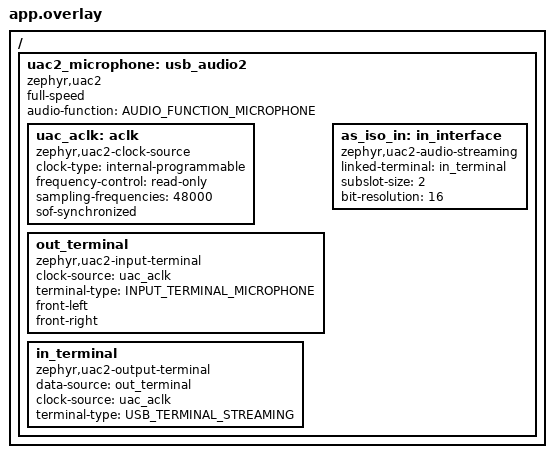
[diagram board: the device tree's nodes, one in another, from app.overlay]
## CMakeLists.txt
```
# SPDX-License-Identifier: Apache-2.0

cmake_minimum_required(VERSION 3.28.0)
find_package(Zephyr REQUIRED HINTS $ENV{ZEPHYR_BASE})
project(bap_broadcast_sink)

target_sources(app PRIVATE
  src/main.c
  src/stream_rx.c
)

target_sources_ifdef(CONFIG_ENABLE_LC3 app PRIVATE src/lc3.c)
target_sources_ifdef(CONFIG_STEREO_AUDIO_OUTPUT app PRIVATE src/stereo_out.c)

if(CONFIG_USE_CODEC_AUDIO_OUTPUT)
  target_sources(app PRIVATE src/hw_codec.c)
endif()

target_sources_ifdef(CONFIG_USE_I2S_CODEC_AUDIO_OUTPUT app PRIVATE src/i2s_codec.c)

if(CONFIG_USE_USB_AUDIO_OUTPUT)
  include(${ZEPHYR_BASE}/samples/subsys/usb/common/common.cmake)
  target_sources(app PRIVATE src/usb.c)
endif()
```

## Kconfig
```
# Copyright (c) 2022 Nordic Semiconductor ASA
# SPDX-License-Identifier: Apache-2.0

mainmenu "Bluetooth: Broadcast Audio Sink"

config SCAN_OFFLOAD
	bool "Whether to wait for a Broadcast Assistant"
	default y
	# enable PAST support if we can
	select BT_PER_ADV_SYNC_TRANSFER_RECEIVER if (!HAS_BT_CTLR || \
							BT_CTLR_SYNC_TRANSFER_RECEIVER_SUPPORT)
	help
	  If set to true, the sample will start advertising connectable for
	  Broadcast Assistants.

config SCAN_SELF
	bool "Whether to scan for Broadcast Sources without Broadcast Assistant"
	default y
	help
	  If set to true, the sample will start scanning for Broadcast Sources
	  without waiting for a Broadcast Assistant to connect.

config SCAN_DELAY
	int "Delay before starting scan (in seconds)"
	range 0 255
	default 10
	depends on SCAN_SELF
	help
	  Time to advertise connectable for a Broadcast Assistant to connect
	  before starting scanning for Broadcast Sources.

config SCAN_BACKGROUND
	bool "Keep background scanning"
	depends on SCAN_SELF
	help
	  Keep scanning in the background.

config TARGET_BROADCAST_NAME
	string "Target Broadcast Device Name"
	default ""
	help
	  Name of target broadcast device. If not empty string, sink device
	  will only listen to the specified broadcast source. Not case sensitive.

config MAX_CODEC_FRAMES_PER_SDU
	int "The maximum number of codec frame per SDU supported"
	default 1
	range 1 255
	help
	  Maximum number of codec frames per SDU supported by this device. Increasing this value
	  allows support for a greater variety of broadcasts, but also increases memory usage.

config ENABLE_LC3
	bool "Enable the LC3 codec"
	# By default let's enable it in the platforms we know are capable of supporting it
	default y
	depends on CPU_HAS_FPU && \
		(ARCH_POSIX || SOC_COMPATIBLE_NRF52X || SOC_COMPATIBLE_NRF5340_CPUAPP || \
			SOC_MIMXRT1062 || SOC_SF32LB525UC6)
	select LIBLC3
	select FPU

config USE_USB_AUDIO_OUTPUT
	bool "Use USB Audio as output"
	depends on ENABLE_LC3
	select USB_DEVICE_STACK_NEXT
	select USBD_AUDIO2_CLASS
	help
	  Enables USB audio as output as a USB peripheral. This does not support providing USB
	  audio to e.g. speakers that are also USB peripherals, but can be connected to e.g. a
	  phone or PC as a USB-in device (such as a USB microphone).
	  USB audio only supports a single audio channel.

config USE_CODEC_AUDIO_OUTPUT
	bool "Use Codec Audio as output"
	depends on ENABLE_LC3
	help
	  Enables codec audio as output. This uses the hardware audio codec for audio playback.
	  Supports audio output through the codec driver.

config USE_SPECIFIC_BROADCAST_CHANNEL
	bool "Use specific Broadcast Channel Audio Location"
	default y
	depends on USE_USB_AUDIO_OUTPUT
	help
	  Enables the use of a specific Channel Audio Location
	  (see config TARGET_BROADCAST_CHANNEL).

config TARGET_BROADCAST_CHANNEL
	int "Broadcast Channel Audio Location to sync to"
	range 0 3
	default 1
	depends on USE_SPECIFIC_BROADCAST_CHANNEL
	help
	  Channel Audio Location to sync to. These corresponds to the bt_audio_location,
	  supporting mono, left and right channels

config INFO_REPORTING_INTERVAL
	int "Number of SDUs received between each information report"
	default 1000
	help
	  Determines how often information about received data is logged.
	  Set to 0 to disable reporting.

# Source common USB sample options used to initialize new experimental USB device stack.
# The scope of these options is limited to USB samples in project tree,
# you cannot use them in your own application.
source "samples/subsys/usb/common/Kconfig.sample_usbd"

source "Kconfig.zephyr"
```

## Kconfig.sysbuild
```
# Copyright 2023 Nordic Semiconductor ASA
# SPDX-License-Identifier: Apache-2.0

source "share/sysbuild/Kconfig"

config NET_CORE_BOARD
	string
	default "nrf5340dk/nrf5340/cpunet" if "$(BOARD)" = "nrf5340dk"
	default "nrf5340_audio_dk/nrf5340/cpunet" if "$(BOARD)" = "nrf5340_audio_dk"
	default "nrf5340bsim/nrf5340/cpunet" if $(BOARD_TARGET_STRING) = "NRF5340BSIM_NRF5340_CPUAPP"
	default "nrf54h20dk/nrf54h20/cpunet" if "$(BOARD)" = "nrf54h20dk"

config NET_CORE_IMAGE_HCI_IPC
	bool "HCI IPC image on network core"
	default y
	depends on NET_CORE_BOARD != ""
```

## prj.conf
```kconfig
CONFIG_BT=y
CONFIG_UTF8=y
CONFIG_BT_AUDIO=y
CONFIG_BT_SMP=y
CONFIG_BT_PAC_SNK=y
CONFIG_BT_PERIPHERAL=y
CONFIG_BT_GAP_AUTO_UPDATE_CONN_PARAMS=n
# Set preferred values based on BT_BAP_CONN_PARAM_RELAXED
CONFIG_BT_PERIPHERAL_PREF_MIN_INT=50
CONFIG_BT_PERIPHERAL_PREF_MAX_INT=70
CONFIG_BT_PERIPHERAL_PREF_LATENCY=0
CONFIG_BT_PERIPHERAL_PREF_TIMEOUT=400
CONFIG_BT_OBSERVER=y
CONFIG_BT_GATT_DYNAMIC_DB=y
CONFIG_BT_EXT_ADV=y
CONFIG_BT_PER_ADV_SYNC=y
CONFIG_BT_ISO_SYNC_RECEIVER=y
CONFIG_BT_BAP_BROADCAST_SINK=y
CONFIG_BT_BAP_SCAN_DELEGATOR=y
CONFIG_BT_ISO_MAX_CHAN=2
# Allocate 4 RX buffers per channel
CONFIG_BT_ISO_RX_BUF_COUNT=8
CONFIG_BT_BAP_BROADCAST_SNK_SUBGROUP_COUNT=2
CONFIG_BT_BAP_BROADCAST_SNK_STREAM_COUNT=2
CONFIG_BT_BAP_BASS_MAX_SUBGROUPS=2
CONFIG_BT_BUF_ACL_RX_SIZE=255
CONFIG_BT_BUF_ACL_TX_SIZE=251
CONFIG_BT_AUDIO_CODEC_CFG_MAX_METADATA_SIZE=64
CONFIG_BT_AUDIO_CODEC_CFG_MAX_DATA_SIZE=64
CONFIG_BT_AUDIO_CODEC_CAP_MAX_METADATA_SIZE=64
CONFIG_BT_AUDIO_CODEC_CAP_MAX_DATA_SIZE=64

CONFIG_BT_DEVICE_NAME="Broadcast Audio Sink"

CONFIG_LOG=y
CONFIG_LOG_BUFFER_SIZE=4096

CONFIG_ASSERT=y
```

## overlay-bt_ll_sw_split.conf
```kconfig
# Zephyr Bluetooth Controller
CONFIG_BT_LL_SW_SPLIT=y

# Enable Extended Advertising, Scanning and Periodic Sync
CONFIG_BT_EXT_ADV=y
CONFIG_BT_PER_ADV_SYNC=y

# Enable Coded PHY support
CONFIG_BT_CTLR_PHY_CODED=y

# Advertising Data Length
CONFIG_BT_CTLR_ADV_DATA_LEN_MAX=50

# Increase Zephyr Bluetooth LE Controller Rx buffer to receive complete chain
# of PDUs
CONFIG_BT_CTLR_RX_BUFFERS=9

# Set maximum scan data length for Extended Scanning in Bluetooth LE Controller
CONFIG_BT_CTLR_SCAN_DATA_LEN_MAX=1650

# Enable support for Broadcast ISO Sync
CONFIG_BT_CTLR_SYNC_ISO=y
CONFIG_BT_CTLR_SCAN_SYNC_ISO_SET=1
CONFIG_BT_CTLR_SYNC_ISO_STREAM_COUNT=2
CONFIG_BT_CTLR_SYNC_ISO_STREAM_MAX=2
CONFIG_BT_CTLR_SYNC_ISO_PDU_LEN_MAX=251

# Supports the highest SDU size required by any BAP LC3 presets (155)
CONFIG_BT_CTLR_SYNC_ISO_PDU_LEN_MAX=251

# Number of supported streams
CONFIG_BT_CTLR_SYNC_ISO_STREAM_MAX=2
CONFIG_BT_CTLR_ISOAL_SINKS=2

# Use link time optimization for code size reduction
CONFIG_ISR_TABLES_LOCAL_DECLARATION=y
CONFIG_LTO=y

# Generate .lst file, to find HCI h/w error event given PC
CONFIG_OUTPUT_DISASSEMBLY=y
CONFIG_OUTPUT_DISASSEMBLY_WITH_SOURCE=y

# Use unreserved scanning and ticker slot window yield
CONFIG_BT_CTLR_ADVANCED_FEATURES=y
CONFIG_BT_CTLR_ADV_RESERVE_MAX=n
CONFIG_BT_CTLR_PERIPHERAL_RESERVE_MAX=n

CONFIG_BT_CTLR_LOW_LAT_ULL=y
CONFIG_BT_CTLR_SCAN_AUX_SET=3
# CONFIG_BT_CTLR_SCAN_AUX_USE_CHAINS=y
# CONFIG_BT_CTLR_SCAN_AUX_CHAIN_COUNT=1
CONFIG_BT_CTLR_SCAN_AUX_SYNC_RESERVE_MIN=y
CONFIG_BT_CTLR_SCAN_UNRESERVED=y
CONFIG_BT_CTLR_SCAN_SLOT_WINDOW=y

CONFIG_BT_CTLR_SYNC_ISO_RESERVE_MAX=n
CONFIG_BT_CTLR_SYNC_ISO_SLOT_WINDOW_JITTER=y

CONFIG_BT_CTLR_ADV_SLOT_WINDOW=y
CONFIG_BT_CTLR_ADV_AUX_SLOT_WINDOW_DRIFT=y

CONFIG_BT_CTLR_LLL_PRIO=0
CONFIG_BT_CTLR_ULL_HIGH_PRIO=1
CONFIG_BT_CTLR_ULL_LOW_PRIO=2

CONFIG_BT_CTLR_LLL_PREPARE_AT_MARGIN=y
CONFIG_BT_CTLR_RADIO_TIMER_ISR=y
CONFIG_BT_CTLR_SW_SWITCH_SINGLE_TIMER=n

CONFIG_BT_TICKER_NEXT_SLOT_GET_MATCH=y
CONFIG_BT_TICKER_EXT=y
CONFIG_BT_TICKER_EXT_EXPIRE_INFO=n
CONFIG_BT_TICKER_EXT_SLOT_WINDOW_YIELD=y

# Enable in-system tests and profiling
CONFIG_BT_CTLR_TEST=y
CONFIG_BT_CTLR_PROFILE_ISR=y

CONFIG_BT_CTLR_ASSERT_OPTIMIZE_FOR_SIZE=n

# CONFIG_ZERO_LATENCY_IRQS=y
# CONFIG_BT_CTLR_ZLI=y
```

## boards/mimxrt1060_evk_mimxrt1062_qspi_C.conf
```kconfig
# Enable Multimedia Pipeline (mpipe) framework on RT1060 EVKC only
CONFIG_MPIPE=y

# liblc3 provides the LC3 decoder and its headers (LC3_MAX_NUM_SAMPLES_MONO,
# LC3_DECODER_MEM_SIZE, etc.) used by the mpipe audio transform.
CONFIG_LIBLC3=y


# mpipe uses zbus message subscribers for the pipeline bus/observer
CONFIG_ZBUS_MSG_SUBSCRIBER=y

# Number of net_buf pools mpipe may register for negotiated buffer pools
CONFIG_MPIPE_NET_BUF_POOL_COUNT=3

# The mpipe streaming thread runs the LC3 decode (lc3_decode) in the transform
# chain function. LC3 decoding needs far more stack than the 1024-byte default,
# so raise the streaming thread stack to avoid a pipeline-thread stack overflow.
CONFIG_MPIPE_THREAD_STACK_SIZE=8192


# Audio output path: I2S/SAI -> hardware codec (WM8962)
CONFIG_I2S=y
# The MCUX SAI driver's TX in_queue/out_queue depth is sized by
# CONFIG_I2S_TX_BLOCK_COUNT: the number of blocks that can be in flight inside
# the SAI DMA queue. With the free-running playback thread the SAI is always
# fed (real PCM or silence), so a small in-flight depth is sufficient.
CONFIG_I2S_TX_BLOCK_COUNT=6

# Output latency budget for the PCM playback path, in LC3 frame blocks
# (10 ms each for this configuration):
#  - prebuffer 4 blocks (~40 ms) is the cushion that absorbs arrival jitter and
#    the drift between the broadcaster clock and the SAI sample clock; it sets
#    the nominal latency.
#  - the ring caps the worst case at 12 blocks (~120 ms) before the oldest
#    block is dropped.
CONFIG_BAP_BROADCAST_SINK_PCM_PREBUFFER_COUNT=4
CONFIG_BAP_BROADCAST_SINK_PCM_BUFFER_PLAY_COUNT=12

# Prime 2 silence blocks into the SAI DMA before starting it, so the frame clock
# is running before the first decoded PCM arrives.
CONFIG_BAP_BROADCAST_SINK_PCM_BUFFER_PRELOAD_COUNT=2

CONFIG_AUDIO=y
CONFIG_AUDIO_CODEC=y
CONFIG_USE_CODEC_AUDIO_OUTPUT=y
CONFIG_USE_I2S_CODEC_TRANSPORT=y
CONFIG_BT_ISO_RX_BUF_COUNT=20
```

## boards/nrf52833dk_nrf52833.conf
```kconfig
# Have Extended Advertising in the background
CONFIG_SCAN_OFFLOAD=n
CONFIG_SCAN_SELF=y
CONFIG_SCAN_BACKGROUND=y

# Enable Full Extended Scanning
CONFIG_BT_EXT_SCAN_BUF_SIZE=1650

# Zephyr Bluetooth LE Controller needs 16 event buffers to generate Extended
# Advertising Report for receiving the complete 1650 bytes of data
CONFIG_BT_BUF_EVT_RX_COUNT=16

CONFIG_BT_LOG_SNIFFER_INFO=y

CONFIG_THREAD_ANALYZER=y
CONFIG_THREAD_ANALYZER_AUTO=y
CONFIG_THREAD_ANALYZER_AUTO_INTERVAL=5
CONFIG_THREAD_NAME=y

CONFIG_LOG=y
CONFIG_LOG_BUFFER_SIZE=4096
```

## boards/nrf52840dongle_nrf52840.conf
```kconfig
# Use USB Audio as audio sink
CONFIG_USE_USB_AUDIO_OUTPUT=y
CONFIG_SAMPLE_USBD_PRODUCT="USB Broadcast Sink sample"

CONFIG_BOARD_SERIAL_BACKEND_CDC_ACM=n
```

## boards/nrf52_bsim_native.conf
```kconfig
# Have Extended Advertising in the background
CONFIG_SCAN_OFFLOAD=y
CONFIG_SCAN_SELF=y
CONFIG_SCAN_BACKGROUND=y

# Enable Full Extended Scanning
CONFIG_BT_EXT_SCAN_BUF_SIZE=1650

# Zephyr Bluetooth LE Controller needs 16 event buffers to generate Extended
# Advertising Report for receiving the complete 1650 bytes of data
CONFIG_BT_BUF_EVT_RX_COUNT=16

CONFIG_CLOCK_CONTROL_NRF_K32SRC_100PPM=y

CONFIG_BT_LOG_SNIFFER_INFO=y
```

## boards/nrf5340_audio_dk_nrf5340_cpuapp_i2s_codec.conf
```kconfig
# Copyright The Zephyr Project Contributors
#
# SPDX-License-Identifier: Apache-2.0

# Use the CS47L63 headphone output instead of USB Audio
CONFIG_USE_I2S_CODEC_AUDIO_OUTPUT=y
```

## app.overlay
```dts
/*
 * Copyright (c) 2025 Nordic Semiconductor ASA
 *
 * SPDX-License-Identifier: Apache-2.0
 */

#include <zephyr/dt-bindings/usb/audio.h>

/ {
	uac2_microphone: usb_audio2 {
		compatible = "zephyr,uac2";
		full-speed;
		audio-function = <AUDIO_FUNCTION_MICROPHONE>;
		status = "okay";

		/* Clock supporting 48KHz
		 *
		 * Since the incoming audio may be between 8 and 48 KHz, we always upsample to 48KHz
		 */
		uac_aclk: aclk {
			compatible = "zephyr,uac2-clock-source";
			clock-type = "internal-programmable";
			frequency-control = "read-only";
			sampling-frequencies = <48000>;
			/* Falsely claim synchronous audio because we
			 * currently don't calculate feedback value
			 */
			sof-synchronized;
		};

		/* The out_terminal supports the incoming Bluetooth LE Audio over ISO
		 * and treats it as a microphone towards the USB host
		 */
		out_terminal: out_terminal {
			compatible = "zephyr,uac2-input-terminal";
			clock-source = <&uac_aclk>;
			terminal-type = <INPUT_TERMINAL_MICROPHONE>;
			front-left;
			front-right;
		};

		/* USB Audio terminal from USB device to USB host */
		in_terminal: in_terminal {
			compatible = "zephyr,uac2-output-terminal";
			data-source = <&out_terminal>;
			clock-source = <&uac_aclk>;
			terminal-type = <USB_TERMINAL_STREAMING>;
		};

		as_iso_in: in_interface {
			compatible = "zephyr,uac2-audio-streaming";
			linked-terminal = <&in_terminal>;
			subslot-size = <2>;
			bit-resolution = <16>;
		};
	};
};
```

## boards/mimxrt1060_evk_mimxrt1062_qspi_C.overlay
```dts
/*
 * Copyright (c) 2026 NXP
 *
 * SPDX-License-Identifier: Apache-2.0
 */

/ {
	aliases {
		/* hw_codec.c resolves the codec through DT_ALIAS(codec0).
		 * audio_codec is the WM8962 node defined in the board DTS.
		 */
		codec0 = &audio_codec;
	};
};

&sai1 {
	mclk-output;
	podf = <15>;
	pll-clocks = <&anatop 0 0 0>,
		     <&anatop 0 0 32>,
		     <&anatop 0 0 1>,
		     <&anatop 0 0 768>,
		     <&anatop 0 0 1000>;
};
```

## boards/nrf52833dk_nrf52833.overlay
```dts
/*
 * Copyright (c) 2025 Nordic Semiconductor ASA
 *
 * SPDX-License-Identifier: Apache-2.0
 */

/* #include "../app.overlay" */
```

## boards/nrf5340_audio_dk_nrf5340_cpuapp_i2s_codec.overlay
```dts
/*
 * Copyright The Zephyr Project Contributors
 *
 * SPDX-License-Identifier: Apache-2.0
 */

#include <zephyr/dt-bindings/input/input-event-codes.h>

/ {
	aliases {
		codec0 = &cs47l63;
		i2s-codec-tx = &i2s0;
	};
};

&clock {
	hfclkaudio-frequency = <12288000>;
};

&hfclkaudio {
	hfclkaudio-frequency = <12288000>;
};

&i2s0 {
	clock-source = "ACLK";
};

&button3 {
	zephyr,code = <INPUT_KEY_MUTE>;
};
```

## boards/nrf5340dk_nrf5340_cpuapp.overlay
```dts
/*
 * Copyright (c) 2025 Nordic Semiconductor ASA
 *
 * SPDX-License-Identifier: Apache-2.0
 */

/*
 * #include "../app.overlay"
 */
```

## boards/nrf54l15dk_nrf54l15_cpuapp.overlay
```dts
/*
 * Copyright (c) 2025 Nordic Semiconductor ASA
 *
 * SPDX-License-Identifier: Apache-2.0
 */

/ {
	chosen {
		zephyr,console = &uart30;
	};
};

&uart30 {
	current-speed = <1000000>;
	status = "okay";
};

&uart20 {
	status = "disabled";
};
```

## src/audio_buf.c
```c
/*
 * SPDX-FileCopyrightText: Copyright The Zephyr Project Contributors
 * SPDX-License-Identifier: Apache-2.0
 */

#include <errno.h>
#include <stddef.h>
#include <stdint.h>
#include <string.h>

#include <zephyr/autoconf.h>
#include <zephyr/kernel.h>
#include <zephyr/sys/printk.h>
#include <zephyr/sys/util.h>

#include "audio_buf.h"

#if DT_HAS_ALIAS(i2s_codec_tx) && IS_ENABLED(CONFIG_I2S) && IS_ENABLED(CONFIG_AUDIO_CODEC)

/* Whole PCM ring buffer size (holds N maximum play blocks). */
#define BAP_PCM_DECODER_BUFFER_SIZE                                                                \
	(BAP_PCM_DATA_PLAY_SIZE_48K * CONFIG_BAP_BROADCAST_SINK_PCM_BUFFER_PLAY_COUNT)

/* Actual usable ring buffer size for the current sample rate. */
static uint32_t pcm_buffer_size;

/* Ring buffer producer/consumer state. */
static volatile uint32_t pcm_r;
static volatile uint32_t pcm_w;
static volatile uint32_t pcm_rm;
static volatile uint32_t pcm_w_count;
static volatile uint32_t pcm_r_count;
static volatile uint32_t pcm_rm_count;

static bool reach_threshold;

static __aligned(4) uint8_t decoded_pcm_buf[BAP_PCM_DECODER_BUFFER_SIZE];

static uint32_t audio_pcm_buffer_free_size(void)
{
	return pcm_buffer_size - (pcm_w_count - pcm_rm_count);
}

static uint32_t audio_add_pcm_data(const uint8_t *data, uint32_t length)
{
	uint32_t free_space;

	free_space = audio_pcm_buffer_free_size();

	if (free_space < length) {
		length = free_space;
	}

	if ((pcm_w + length) <= pcm_buffer_size) {
		if (data != NULL) {
			memcpy(&decoded_pcm_buf[pcm_w], data, length);
		} else {
			memset(&decoded_pcm_buf[pcm_w], 0, length);
		}

		pcm_w += length;
	} else {
		uint32_t first = pcm_buffer_size - pcm_w;

		if (data != NULL) {
			memcpy(&decoded_pcm_buf[pcm_w], data, first);
			memcpy(&decoded_pcm_buf[0], &data[first], length - first);
		} else {
			memset(&decoded_pcm_buf[pcm_w], 0, first);
			memset(&decoded_pcm_buf[0], 0, length - first);
		}

		pcm_w = length - first;
	}
	pcm_w_count += length;

	if (pcm_w == pcm_buffer_size) {
		pcm_w = 0;
	}

	return length;
}

int audio_media_sync(uint8_t *data, uint16_t datalen)
{
	if (data != NULL) {
		pcm_rm += datalen;
		pcm_rm_count += datalen;

		if (pcm_rm >= pcm_buffer_size) {
			pcm_rm -= pcm_buffer_size;
		}
	}

	return 0;
}

void audio_get_pcm_data(uint8_t **data, uint32_t length)
{
	uint32_t data_space;
	uint32_t w_count = pcm_w_count;
	uint32_t r_count = pcm_r_count;

	data_space = w_count - r_count;

	if (!reach_threshold) {
		if (data_space > CONFIG_BAP_BROADCAST_SINK_BOARD_CODEC_PLAY_THRESHOLD *
				 pcm_buffer_size / 100U) {
			reach_threshold = true;
		} else {
			*data = NULL;
			return;
		}
	}

	if (data_space < length) {
		*data = NULL;
		reach_threshold = false;
	} else {
		pcm_r_count += length;
		*data = &decoded_pcm_buf[pcm_r];
		pcm_r += length;

		if (pcm_r >= pcm_buffer_size) {
			pcm_r = 0;
		}
	}
}

void audio_feed_pcm_lc3(const uint8_t *data, size_t len, uint8_t channels)
{
	if ((data == NULL) || (len == 0U) || (channels == 0U)) {
		return;
	}

	/* The playback path always operates on stereo interleaved samples.
	 * If the decoded LC3 frame is mono, duplicate each sample to both
	 * channels; if it is already stereo (or more), pass through and let
	 * the sink truncate any additional channels.
	 */
	if (channels == 1U) {
		const int16_t *src = (const int16_t *)data;
		const size_t samples = len / sizeof(int16_t);
		int16_t frame[2];

		for (size_t i = 0U; i < samples; i++) {
			frame[0] = src[i];
			frame[1] = src[i];
			(void)audio_add_pcm_data((const uint8_t *)frame, sizeof(frame));
		}
	} else {
		(void)audio_add_pcm_data(data, len);
	}
}

void audio_buf_reset(uint32_t fs)
{
	uint32_t block;

	pcm_r = 0;
	pcm_w = 0;
	pcm_rm = 0;
	pcm_w_count = 0;
	pcm_r_count = 0;
	pcm_rm_count = 0;
	reach_threshold = false;

	switch (fs) {
	case 8000:
		block = BAP_PCM_DATA_PLAY_SIZE_8K;
		break;
	case 16000:
		block = BAP_PCM_DATA_PLAY_SIZE_16K;
		break;
	case 24000:
		block = BAP_PCM_DATA_PLAY_SIZE_24K;
		break;
	case 32000:
		block = BAP_PCM_DATA_PLAY_SIZE_32K;
		break;
	case 48000:
		block = BAP_PCM_DATA_PLAY_SIZE_48K;
		break;
	default:
		printk("wrong frequency\n");
		return;
	}

	pcm_buffer_size = BAP_PCM_DECODER_BUFFER_SIZE - (BAP_PCM_DECODER_BUFFER_SIZE % block);
}

#else

void audio_buf_reset(uint32_t fs)
{
	ARG_UNUSED(fs);
}

void audio_feed_pcm_lc3(const uint8_t *data, size_t len, uint8_t channels)
{
	ARG_UNUSED(data);
	ARG_UNUSED(len);
	ARG_UNUSED(channels);
}

#endif
```

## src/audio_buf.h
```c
/*
 * SPDX-FileCopyrightText: Copyright The Zephyr Project Contributors
 * SPDX-License-Identifier: Apache-2.0
 */

#ifndef ZEPHYR_INCLUDE_AUDIO_BUF_H_
#define ZEPHYR_INCLUDE_AUDIO_BUF_H_

#include <stddef.h>
#include <stdint.h>

/* Played PCM block is 10 ms of stereo 16-bit samples. */
#define BAP_PCM_DATA_PLAY_SIZE(_fs) (((_fs) / 100U) * 2U * 2U)

#define BAP_PCM_DATA_PLAY_SIZE_8K  BAP_PCM_DATA_PLAY_SIZE(8000)
#define BAP_PCM_DATA_PLAY_SIZE_16K BAP_PCM_DATA_PLAY_SIZE(16000)
#define BAP_PCM_DATA_PLAY_SIZE_24K BAP_PCM_DATA_PLAY_SIZE(24000)
#define BAP_PCM_DATA_PLAY_SIZE_32K BAP_PCM_DATA_PLAY_SIZE(32000)
#define BAP_PCM_DATA_PLAY_SIZE_48K BAP_PCM_DATA_PLAY_SIZE(48000)

void audio_buf_reset(uint32_t fs);

/* Feed decoded LC3 PCM into the playback ring buffer. */
void audio_feed_pcm_lc3(const uint8_t *data, size_t len, uint8_t channels);

int audio_media_sync(uint8_t *data, uint16_t datalen);

void audio_get_pcm_data(uint8_t **data, uint32_t length);

#endif /* ZEPHYR_INCLUDE_AUDIO_BUF_H_ */
```

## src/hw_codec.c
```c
/**
 * @file
 * @brief Bluetooth BAP Broadcast Sink audio codec integration
 *
 * This file handles all the audio codec hardware integration for the sample.
 *
 * Two codec integration models are supported and selected at compile time:
 *
 *  - Path A (control-only codec): the codec driver only implements the codec
 *    control API (for example the WM8962 on NXP i.MX RT boards). Such a codec
 *    cannot pull or write PCM samples itself, so the PCM data is transported to
 *    the codec over the SoC SAI/I2S peripheral by hw_codec_i2s.c. This module
 *    owns the codec control (audio_codec_configure / start_output / stop_output
 *    / volume) while hw_codec_i2s.c owns the SAI/I2S data path.
 *    This path is selected when the board provides an "i2s-codec-tx"
 *    devicetree alias and both CONFIG_I2S and CONFIG_AUDIO_CODEC are enabled.
 *
 *  - Path B (smart codec): the codec driver implements a done callback and an
 *    audio_codec_write() entry point, so PCM samples are pulled from an
 *    internal ring buffer whenever the codec requests a new block. This is the
 *    default path used when no I2S transport alias is present.
 *
 * Both models are hidden behind the same hw_codec_open / hw_codec_cfg /
 * hw_codec_write_data / hw_codec_close facade, so the mpipe and non-mpipe
 * callers do not need to know which model is in use.
 *
 * Copyright (c) 2025 SiFli Technologies(Nanjing) Co., Ltd
 * Copyright (c) 2026 NXP
 *
 * SPDX-License-Identifier: Apache-2.0
 */


#include <errno.h>
#include <stdbool.h>
#include <stddef.h>
#include <stdint.h>

#include <zephyr/autoconf.h>
#include <zephyr/device.h>
#include <zephyr/devicetree.h>
#include <zephyr/kernel.h>
#include <zephyr/logging/log.h>
#include <zephyr/audio/codec.h>
#include <zephyr/sys/ring_buffer.h>
#include <zephyr/toolchain.h>

LOG_MODULE_REGISTER(codec, CONFIG_LOG_DEFAULT_LEVEL);

/*
 * Select Path A (control-only codec + SAI/I2S PCM transport) when the user
 * enables CONFIG_USE_I2S_CODEC_TRANSPORT. Otherwise fall back to Path B
 * (smart codec with its own host interface).
 */

/*
 * Default speaker/output volume sent via AUDIO_PROPERTY_OUTPUT_VOLUME.
 *
 * The valid numeric range and exact mapping to dB are codec-dependent; refer
 * to the specific codec driver / datasheet for details. The value 15 was
 * selected as a conservative, comfortable default for this sample application
 * to avoid an excessively loud/noisy output during testing.
 * Adjust as needed to match the desired default output level.
 */
#define SPEAKER_VOL 15U



#if CONFIG_USE_I2S_CODEC_TRANSPORT
/* ---------------------------------------------------------------------------
 * Path A: control-only codec (for example WM8962) with SAI/I2S PCM transport.
 * -------------------------------------------------------------------------
 */


#include "hw_codec_i2s.h"

static const struct device *g_dev;
static bool codec_configured;

int hw_codec_open(void)
{
	int ret;

	/*
	 * Idempotent: the codec is opened from the stream "started" callback,
	 * and the audio data path may also open it while bringing itself up.
	 * Opening twice is harmless but re-initialising the transport under a
	 * running stream is not, so return early once the device is held.
	 */
	if (g_dev != NULL) {
		return 0;
	}

	g_dev = DEVICE_DT_GET(DT_ALIAS(codec0));
	if (!device_is_ready(g_dev)) {
		LOG_ERR("Could not open codec device");
		g_dev = NULL;
		return -EIO;
	}

	ret = hw_codec_i2s_init();
	if (ret != 0) {
		LOG_ERR("Failed to init I2S transport (err %d)", ret);
		g_dev = NULL;
		return ret;
	}

	return 0;
}

int hw_codec_cfg(uint32_t samplerate, uint32_t frame_dur_us, uint8_t channels)
{
	int ret;
	audio_property_value_t val = {.vol = SPEAKER_VOL};
	struct audio_codec_cfg cfg = {
		.dai_type = AUDIO_DAI_TYPE_I2S,
		.dai_route = AUDIO_ROUTE_PLAYBACK,
		.dai_cfg.i2s.word_size = CODEC_PCM_WIDTH_BITS,
		.dai_cfg.i2s.channels = channels,
		.dai_cfg.i2s.format = I2S_FMT_DATA_FORMAT_I2S,
#ifdef CONFIG_USE_CODEC_CLOCK
		.dai_cfg.i2s.options = I2S_OPT_BIT_CLK_CONTROLLER | I2S_OPT_FRAME_CLK_CONTROLLER,
#else
		.dai_cfg.i2s.options = I2S_OPT_BIT_CLK_TARGET | I2S_OPT_FRAME_CLK_TARGET,
#endif
		.dai_cfg.i2s.frame_clk_freq = samplerate,
		/*
		 * mem_slab and block_size are intentionally left unset here:
		 * they only matter to the SoC I2S peripheral, which is
		 * configured separately in hw_codec_i2s_cfg(). The codec control
		 * driver (for example WM8962) ignores these two fields. This is
		 * unlike a2dp_sink, which reuses a single struct for both the
		 * audio_codec_configure() and the i2s_configure() calls and thus
		 * has to populate them.
		 */
	};

	if (codec_configured) {
		LOG_WRN("Already configured");
		return -EALREADY;
	}

	LOG_INF("codec (I2S): samplerate=%u channels=%u frame_dur=%u us", samplerate,
		channels, frame_dur_us);

	ret = audio_codec_configure(g_dev, &cfg);
	if (ret != 0) {
		LOG_ERR("Failed to configure codec (err %d)", ret);
		return ret;
	}

	k_msleep(1000);

	ret = hw_codec_i2s_cfg(samplerate, channels, frame_dur_us);
	if (ret != 0) {
		LOG_ERR("Failed to configure I2S transport (err %d)", ret);
		return ret;
	}

	audio_codec_start_output(g_dev);

	ret = audio_codec_set_property(g_dev, AUDIO_PROPERTY_OUTPUT_VOLUME, 0, val);
	if (ret != 0) {
		LOG_ERR("Failed to set codec output volume (err %d)", ret);
		audio_codec_stop_output(g_dev);
		return ret;
	}

	codec_configured = true;

	return 0;
}

uint32_t hw_codec_write_data(const uint8_t *data, uint32_t len)
{
	return hw_codec_i2s_write(data, len);
}

int hw_codec_close(void)
{
	if (g_dev != NULL && codec_configured) {
		(void)hw_codec_i2s_close();
		audio_codec_stop_output(g_dev);
		codec_configured = false;
		return 0;
	} else {
		return -EIO;
	}
}

#else /* !CONFIG_USE_I2S_CODEC_TRANSPORT */
/* ---------------------------------------------------------------------------
 * Path B: smart codec (pull-driven via done callback + audio_codec_write).
 * -------------------------------------------------------------------------
 */


/*
 * Size of one audio block transferred to the codec, in bytes.
 *
 * For the configuration used here (16bit samples, mono channel),
 * 480 bytes correspond to 240 PCM samples per block. This value was
 * chosen as a compromise between:
 *  - keeping latency reasonably low (smaller blocks)
 *  - avoiding excessive interrupt / DMA overhead (larger blocks).
 * If the PCM format (sample width or number of channels) is changed,
 * this constant should be revisited so that the block size remains
 * appropriate for the target use case and hardware.
 */
#define CODEC_BLOCK_SIZE 480U

/*
 * Total size of the ring buffer used to queue audio data for the codec.
 *
 * The buffer is sized to hold 20 CODEC_BLOCK_SIZE blocks. Having multiple
 * blocks queued reduces the likelihood of underruns when the producer is
 * briefly delayed, while still keeping overall latency and RAM usage
 * bounded. Increasing the multiplier adds buffering (and latency / RAM
 * consumption); decreasing it reduces buffering but makes underruns more
 * likely on a busy system.
 */
#define RING_BUF_SIZE (CODEC_BLOCK_SIZE * 20U)

static uint8_t ring_buffer[RING_BUF_SIZE];
static struct ring_buf rb;
static bool codec_configured;
static uint8_t block_data[CODEC_BLOCK_SIZE];
static const struct device *g_dev;

static void tx_done(const struct device *dev, void *user_data)
{
	uint32_t avail;
	uint32_t read;
	int written;

	ARG_UNUSED(user_data);

	avail = ring_buf_size_get(&rb);
	if (avail < CODEC_BLOCK_SIZE) {
		LOG_WRN("Buffer does not have enough data for a full block");
		return;
	}

	read = ring_buf_get(&rb, block_data, CODEC_BLOCK_SIZE);
	if (read != CODEC_BLOCK_SIZE) {
		LOG_WRN("Failed to read full block from ring buffer: %u bytes", read);
		return;
	}

	written = audio_codec_write(dev, block_data, CODEC_BLOCK_SIZE);
	if (written != CODEC_BLOCK_SIZE) {
		LOG_WRN("Failed to write full block data to audio device: %u bytes", written);
		return;
	}
}

int hw_codec_open(void)
{
	/*
	 * Idempotent: the codec is opened from the stream "started" callback,
	 * and the audio data path may also open it while bringing itself up.
	 * Returning early keeps a second open from resetting the ring buffer
	 * under a codec that is already streaming.
	 */
	if (g_dev != NULL) {
		return 0;
	}

	g_dev = DEVICE_DT_GET(DT_ALIAS(codec0));
	if (!device_is_ready(g_dev)) {
		LOG_ERR("Could not open codec device");
		g_dev = NULL;
		return -EIO;
	}
	ring_buf_init(&rb, RING_BUF_SIZE, ring_buffer);
	return 0;
}

int hw_codec_cfg(uint32_t samplerate, uint32_t frame_dur_us, uint8_t channels)
{
	int ret;
	audio_property_value_t val = {.vol = SPEAKER_VOL};
	struct audio_codec_cfg cfg = {
		.dai_type = AUDIO_DAI_TYPE_PCM,
		.dai_cfg.pcm.dir = AUDIO_DAI_DIR_TX,
		.dai_cfg.pcm.pcm_width = AUDIO_PCM_WIDTH_16_BITS,
		.dai_cfg.pcm.channels = 1U,
		.dai_cfg.pcm.block_size = CODEC_BLOCK_SIZE,
		.dai_cfg.pcm.samplerate = samplerate,
	};

	/*
	 * The smart-codec path pulls fixed-size blocks (CODEC_BLOCK_SIZE) from
	 * its own ring buffer, so the codec frame duration does not affect its
	 * configuration.
	 */
	ARG_UNUSED(frame_dur_us);
	ARG_UNUSED(channels);

	if (codec_configured) {
		LOG_WRN("Already configured");
		return -EALREADY;
	}

	LOG_INF("codec: samplerate=%d block_size=%d", samplerate, CODEC_BLOCK_SIZE);
	audio_codec_register_done_callback(g_dev, tx_done, NULL, NULL, NULL);
	ret = audio_codec_configure(g_dev, &cfg);
	if (ret != 0) {
		LOG_ERR("Failed to configure codec (err %d)", ret);
		return ret;
	}

	ret = audio_codec_start(g_dev, AUDIO_DAI_DIR_TX);
	if (ret != 0) {
		LOG_ERR("Failed to start codec (err %d)", ret);
		return ret;
	}

	ret = audio_codec_set_property(g_dev, AUDIO_PROPERTY_OUTPUT_VOLUME, 0, val);
	if (ret != 0) {
		LOG_ERR("Failed to set codec output volume (err %d)", ret);
		if (audio_codec_stop(g_dev, AUDIO_DAI_DIR_TX) < 0) {
			LOG_ERR("Failed to stop codec");
		}
		return ret;
	}
	codec_configured = true;

	return 0;
}

uint32_t hw_codec_write_data(const uint8_t *data, uint32_t len)
{
	uint32_t bytes_put;

	bytes_put = ring_buf_put(&rb, data, len);
	if (bytes_put != len) {
		LOG_WRN("Buffer full, only added %u bytes", bytes_put);
	}
	return bytes_put;
}

int hw_codec_close(void)
{
	if (g_dev != NULL && codec_configured) {
		int ret = audio_codec_stop(g_dev, AUDIO_DAI_DIR_TX);

		if (ret < 0) {
			return ret;
		}
		ring_buf_reset(&rb);
		codec_configured = false;
		return 0;
	} else {
		return -EIO;
	}
}

#endif /* CONFIG_USE_I2S_CODEC_TRANSPORT */
```

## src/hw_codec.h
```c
/**
 * @file
 * @brief Bluetooth BAP Broadcast Sink sample audio codec header
 *
 * This file declares the audio codec related functionality for the sample
 *
 * Copyright (c) 2025 SiFli Technologies(Nanjing) Co., Ltd
 *
 * SPDX-License-Identifier: Apache-2.0
 */

#ifndef SAMPLE_BAP_BROADCAST_SINK_HW_CODEC_H
#define SAMPLE_BAP_BROADCAST_SINK_HW_CODEC_H
#include <stddef.h>
#include <stdint.h>

/**
 * @brief Open and initialize the audio codec.
 *
 * This function prepares the audio codec for use, allocating and
 * initializing any required resources.
 *
 * @retval 0        On success.
 * @return negative On failure, with a negative error code.
 */
int hw_codec_open(void);

/**
 * @brief Configure the audio codec sampling rate.
 *
 * This function applies the desired sampling rate to the audio codec.
 * It must be called after @ref hw_codec_open and before sending
 * audio data with @ref hw_codec_write_data.
 *
 * @param samplerate Sampling rate in Hz (for example, 48000 for 48 kHz).
 *
 * @retval 0        On success.
 * @retval -EALREADY If the codec is already configured.
 * @return negative  On other failures, with a negative error code.
 */
int hw_codec_cfg(uint32_t samplerate);

/**
 * @brief Write audio data to the codec for playback.
 *
 * This function sends raw audio samples to the codec. It should be
 * called after the codec has been opened and configured.
 *
 * @param data Pointer to the buffer containing audio data.
 * @param len  Number of bytes of audio data to write.
 *
 * @return The number of bytes successfully queued in the internal buffer.
 *         A value less than @p len indicates a partial enqueue. The actual
 *         transfer of the queued data to the codec hardware happens
 *         asynchronously.
 */
uint32_t hw_codec_write_data(const uint8_t *data, uint32_t len);

/**
 * @brief Close the audio codec and release resources.
 *
 * This function stops the codec if necessary and frees any resources
 * that were allocated by @ref hw_codec_open.
 *
 * @retval 0    On success.
 * @retval -EIO If the codec has not been opened or configured.
 */
int hw_codec_close(void);

#endif /* SAMPLE_BAP_BROADCAST_SINK_HW_CODEC_H */
```

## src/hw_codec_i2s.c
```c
/**
 * @file
 * @brief BAP Broadcast Sink I2S/SAI PCM transport (hardware layer).
 *
 * This module implements the hardware-specific SAI/I2S data path used by
 * hw_codec.c on boards whose codec is a control-only device (for example the
 * WM8962 on NXP i.MX RT boards). The codec driver on such boards only
 * implements the control API, so the PCM samples are transported to the codec
 * over the SoC SAI/I2S peripheral using the Zephyr I2S driver API
 * (i2s_configure / i2s_write / i2s_trigger).
 *
 * Responsibility split:
 *  - hw_codec.c owns the codec control (audio_codec_configure /
 *    start_output / stop_output / volume).
 *  - this module owns the SAI/I2S peripheral configuration and the DMA memory
 *    slab (a hardware/DMA resource).
 *  - i2s_play.c owns the software playback policy: the elastic PCM ring buffer
 *    and the playback thread that keeps the SAI DMA fed. This module hands the
 *    configured device, the DMA slab, the per-block size and the frame
 *    duration to i2s_play via i2s_play_setup().
 *
 * This file is only compiled when the board provides an i2s-codec-tx
 * devicetree alias (see CMakeLists.txt).
 *
 * Copyright (c) 2025 NXP
 *
 * SPDX-License-Identifier: Apache-2.0
 */

#include <errno.h>
#include <stdbool.h>
#include <stddef.h>
#include <stdint.h>

#include <zephyr/autoconf.h>
#include <zephyr/device.h>
#include <zephyr/devicetree.h>
#include <zephyr/kernel.h>
#include <zephyr/logging/log.h>
#include <zephyr/drivers/i2s.h>
#include <zephyr/toolchain.h>

#include "hw_codec_i2s.h"
#include "i2s_play.h"

LOG_MODULE_REGISTER(codec_i2s, CONFIG_LOG_DEFAULT_LEVEL);

#define I2S_TX_NODE DT_ALIAS(i2s_codec_tx)

#define I2S_TX_TIMEOUT_MS (2000U)

/* Fallback default in case the Kconfig option is not selected. */
#ifndef CONFIG_BAP_BROADCAST_SINK_PCM_BUFFER_PLAY_COUNT
#define CONFIG_BAP_BROADCAST_SINK_PCM_BUFFER_PLAY_COUNT 12
#endif

/* Depth of the elastic PCM ring between producer and playback thread. */
#define PCM_RING_DEPTH CONFIG_BAP_BROADCAST_SINK_PCM_BUFFER_PLAY_COUNT

/*
 * One I2S transfer block holds the interleaved PCM samples produced by the LC3
 * decoder for a single LC3 frame. The block size in bytes is computed at run
 * time from the actual stream parameters:
 *
 *   samples_per_frame = samplerate * frame_dur_us / 1000000
 *   block_size        = samples_per_frame * (word_size / 8) * channels
 *
 * The size is driven by the LC3 frame duration (per the BT LE Audio spec this
 * is either 7500 us or 10000 us), NOT by the ISO interval. ISO interval jitter
 * is absorbed by the PCM ring and the multi-block DMA slab.
 */
#define CODEC_PCM_MAX_CHANNELS 2U
#define CODEC_PCM_MAX_SAMPLERATE 48000U
#define CODEC_PCM_MAX_FRAME_DUR_US 10000U
#define CODEC_PCM_BYTES_PER_SAMPLE (CODEC_PCM_WIDTH_BITS / 8U)

/*
 * Worst-case bytes for a single block, used to statically size the DMA slab.
 * Worst case is 48 kHz, 10 ms, stereo:
 * 48000 * 10000 / 1000000 = 480 samples * 2 bytes * 2 channels = 1920 bytes.
 */
#define I2S_TX_MAX_BLOCK_SIZE\
	(((CODEC_PCM_MAX_SAMPLERATE * CODEC_PCM_MAX_FRAME_DUR_US) / 1000000U) *\
	 CODEC_PCM_BYTES_PER_SAMPLE * CODEC_PCM_MAX_CHANNELS)

/*
 * Total slab blocks: the ring can hold up to PCM_RING_DEPTH filled blocks that
 * have not yet been handed to the SAI, plus up to CONFIG_I2S_TX_BLOCK_COUNT
 * blocks in flight inside the SAI DMA queue, plus a couple of scratch/silence
 * blocks owned by the playback thread. Size the slab for the sum so the
 * producer and consumer never contend for the same pool.
 */
#define I2S_TX_SLAB_BLOCKS (PCM_RING_DEPTH + CONFIG_I2S_TX_BLOCK_COUNT + 2U)

#if defined(CONFIG_NOCACHE_MEMORY)
#define __NOCACHE __attribute__((__section__(".nocache")))
#elif defined(CONFIG_DT_DEFINED_NOCACHE)
#define __NOCACHE __attribute__((__section__(CONFIG_DT_DEFINED_NOCACHE_NAME)))
#else
#define __NOCACHE
#endif

/* DMA memory slab shared by the PCM and silence blocks (hardware resource). */
static __NOCACHE __aligned(4) uint8_t tx_slab_buffer[I2S_TX_SLAB_BLOCKS * I2S_TX_MAX_BLOCK_SIZE];
static struct k_mem_slab tx_mem_slab;

static const struct device *i2s_tx_dev;

/* Set once the DMA slab has been initialised, to detect a reconfiguration. */
static bool tx_slab_initialised;

int hw_codec_i2s_init(void)
{
	i2s_tx_dev = DEVICE_DT_GET(I2S_TX_NODE);
	if (!device_is_ready(i2s_tx_dev)) {
		LOG_ERR("I2S tx device not ready");
		return -EIO;
	}

	return 0;
}

int hw_codec_i2s_cfg(uint32_t samplerate, uint8_t channels, uint32_t frame_dur_us)
{
	int ret;
	uint32_t samples_per_frame;
	uint32_t block_size;

	if ((channels == 0U || channels > CODEC_PCM_MAX_CHANNELS) ||
	    (samplerate == 0U || samplerate > CODEC_PCM_MAX_SAMPLERATE) ||
	    (frame_dur_us == 0U)) {
		LOG_ERR("Unsupported Parameter");
		return -EINVAL;
	}

	/* Clamp to the worst case the DMA slab is sized for (10 ms). */
	if (frame_dur_us > CODEC_PCM_MAX_FRAME_DUR_US) {
		LOG_WRN("Frame duration %u us exceeds max, clamping to %u us", frame_dur_us,
			CODEC_PCM_MAX_FRAME_DUR_US);
		frame_dur_us = CODEC_PCM_MAX_FRAME_DUR_US;
	}

	/*
	 * Number of PCM samples per channel in one LC3 frame. Microsecond math
	 * keeps the 7.5 ms case exact (48 kHz * 7500 / 1000000 = 360 samples).
	 */
	samples_per_frame = (uint32_t)(((uint64_t)samplerate * frame_dur_us) / 1000000U);

	/* samples_per_frame * bytes_per_sample * channels */
	block_size = samples_per_frame * CODEC_PCM_BYTES_PER_SAMPLE * channels;

	if (block_size == 0U || block_size > I2S_TX_MAX_BLOCK_SIZE) {
		LOG_ERR("Computed block size %u out of range (max %u)", block_size,
			I2S_TX_MAX_BLOCK_SIZE);
		return -EINVAL;
	}

	/*
	 * Reconfiguring the slab would reset its free list while the SAI DMA
	 * and the playback thread may still hold blocks carved out of the old
	 * partition, leaking those blocks and letting two owners write the same
	 * memory. Require a close (which stops playback and drains the ring)
	 * before the stream can be configured again.
	 */
	if (tx_slab_initialised && k_mem_slab_num_used_get(&tx_mem_slab) != 0U) {
		LOG_ERR("I2S tx reconfigure with %u blocks still in use",
			k_mem_slab_num_used_get(&tx_mem_slab));
		return -EBUSY;
	}

	/*
	 * Initialise the DMA slab before i2s_configure(): the configuration
	 * stores the mem_slab pointer in the driver and the driver may allocate
	 * from it as soon as the stream is configured, so the slab must already
	 * describe a valid partition at that point.
	 */
	k_mem_slab_init(&tx_mem_slab, tx_slab_buffer, block_size, I2S_TX_SLAB_BLOCKS);
	tx_slab_initialised = true;

	struct i2s_config i2s_cfg = {
		.word_size = CODEC_PCM_WIDTH_BITS,
		.channels = channels,
		.format = I2S_FMT_DATA_FORMAT_I2S,
		/*
		 * Clock roles are deliberately the mirror image of the codec
		 * configuration in hw_codec.c: the SAI and the codec are peers
		 * on the same I2S bus, so exactly one of them must drive BCK
		 * and WS. CONFIG_USE_CODEC_CLOCK selects the codec as the clock
		 * source, which makes the SAI the target here.
		 */
#ifdef CONFIG_USE_CODEC_CLOCK
		.options = I2S_OPT_BIT_CLK_TARGET | I2S_OPT_FRAME_CLK_TARGET,
#else
		.options = I2S_OPT_BIT_CLK_CONTROLLER | I2S_OPT_FRAME_CLK_CONTROLLER,
#endif
		.frame_clk_freq = samplerate,
		.block_size = block_size,
		.mem_slab = &tx_mem_slab,
		.timeout = I2S_TX_TIMEOUT_MS,
	};

	ret = i2s_configure(i2s_tx_dev, I2S_DIR_TX, &i2s_cfg);
	if (ret != 0) {
		LOG_ERR("Failed to configure I2S tx (err %d)", ret);
		return ret;
	}

	/* Hand the hardware handles to the pure-software playback layer. */
	i2s_play_setup(i2s_tx_dev, &tx_mem_slab, block_size, frame_dur_us);

	LOG_INF("I2S tx: rate=%u channels=%u block_size=%u", samplerate, channels, block_size);

	return 0;
}

uint32_t hw_codec_i2s_write(const uint8_t *data, uint32_t len)
{
	return i2s_play_write(data, len);
}

int hw_codec_i2s_close(void)
{
	/*
	 * i2s_play_stop() joins the playback thread, which drops the transmit
	 * stream and returns every block it owned to the slab, so the stream is
	 * already stopped and the slab fully reclaimed when this returns.
	 */
	i2s_play_stop();

	return 0;
}
```

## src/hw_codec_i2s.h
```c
/**
 * @file
 * @brief BAP Broadcast Sink I2S/SAI PCM transport public interface.
 *
 * This header declares the SAI/I2S data path helpers used by hw_codec.c on
 * boards whose codec is a control-only device (for example the WM8962 on NXP
 * i.MX RT boards). The codec control driver only implements the control API,
 * so the PCM samples are transported to the codec over the SoC SAI/I2S
 * peripheral using the Zephyr I2S driver API.
 *
 * Copyright (c) 2025 NXP
 *
 * SPDX-License-Identifier: Apache-2.0
 */

#ifndef BAP_BROADCAST_SINK_HW_CODEC_I2S_H_
#define BAP_BROADCAST_SINK_HW_CODEC_I2S_H_

#include <stdint.h>

/*
 * PCM sample width in bits.
 *
 * The per-block size and the channel count are no longer fixed: the block
 * size is computed at run time in hw_codec_i2s_cfg() from the sample rate,
 * this sample width and the number of channels passed in, so multi-BIS
 * (stereo and beyond) and different sample rates are handled automatically.
 */
#define CODEC_PCM_WIDTH_BITS 16U


/**
 * @brief Initialise the I2S tx device and DMA memory slab.
 *
 * @return 0 on success, negative errno otherwise.
 */
int hw_codec_i2s_init(void);

/**
 * @brief Configure the I2S tx stream for the given sample rate, channels and
 *        LC3 frame duration.
 *
 * The per-block size is computed at run time from the sample rate, PCM sample
 * width, the number of channels and the LC3 frame duration, so the same call
 * adapts to different sample rates, frame durations and BIS counts (mono,
 * stereo, ...). The block size follows the LC3 frame duration (per the BT LE
 * Audio spec, either 7500 us or 10000 us), not the ISO interval.
 *
 * @param samplerate   PCM frame clock frequency in Hz.
 * @param channels     Number of interleaved PCM channels (BIS streams rendered).
 * @param frame_dur_us LC3 frame duration in microseconds (7500 or 10000).
 *
 * @return 0 on success, negative errno otherwise.
 */
int hw_codec_i2s_cfg(uint32_t samplerate, uint8_t channels, uint32_t frame_dur_us);


/**
 * @brief Queue PCM data to the I2S tx stream.
 *
 * @param data Pointer to the PCM sample buffer.
 * @param len  Number of bytes to write.
 *
 * @return Number of bytes accepted.
 */
uint32_t hw_codec_i2s_write(const uint8_t *data, uint32_t len);

/**
 * @brief Drain and stop the I2S tx stream.
 *
 * @return 0 on success, negative errno otherwise.
 */
int hw_codec_i2s_close(void);

#endif /* BAP_BROADCAST_SINK_HW_CODEC_I2S_H_ */
```

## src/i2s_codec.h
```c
/**
 * @file
 * @brief Bluetooth BAP Broadcast Sink sample I2S codec output header
 *
 * Copyright The Zephyr Project Contributors
 *
 * SPDX-License-Identifier: Apache-2.0
 */

#ifndef SAMPLE_BAP_BROADCAST_SINK_I2S_CODEC_H
#define SAMPLE_BAP_BROADCAST_SINK_I2S_CODEC_H

/**
 * @brief Initialize the I2S codec output
 *
 * Configures the codec and the I2S controller and starts playing the stereo output buffer
 *
 * @retval 0 Success
 * @retval -EALREADY Already initialized
 * @retval -ENODEV The codec or the I2S controller is not ready
 * @retval <0 Negative errno from the codec, I2S or memory slab call that failed
 */
int i2s_codec_init(void);

#endif /* SAMPLE_BAP_BROADCAST_SINK_I2S_CODEC_H */
```

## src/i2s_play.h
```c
/**
 * @file
 * @brief BAP Broadcast Sink I2S playback logic.
 *
 * This module is the pure-software playback layer that sits on top of the
 * hardware-specific SAI/I2S transport in hw_codec_i2s.c. It owns:
 *  - an elastic PCM ring buffer that decouples the LC3 decoder (producer) from
 *    the SAI (consumer), and
 *  - a playback thread that keeps the SAI DMA fed, with a prebuffer latch that
 *    builds a cushion before playing so ordinary arrival jitter is not
 *    mistaken for an underrun.
 *
 * It contains no hardware register access: the SAI device handle, the DMA
 * memory slab, the per-block size and the frame duration are supplied by
 * hw_codec_i2s.c through i2s_play_setup(). This keeps the hardware
 * configuration (hw_codec_i2s.c) separate from the playback/buffering policy
 * (this file).
 *
 * Copyright (c) 2026 NXP
 *
 * SPDX-License-Identifier: Apache-2.0
 */

#ifndef BAP_BROADCAST_SINK_I2S_PLAY_H_
#define BAP_BROADCAST_SINK_I2S_PLAY_H_

#include <stdint.h>

#include <zephyr/device.h>
#include <zephyr/kernel.h>

/**
 * @brief Provide the hardware handles and stream timing used for playback.
 *
 * Called by hw_codec_i2s_cfg() after the SAI/I2S peripheral has been
 * configured and the DMA memory slab initialised. The playback module
 * initialises its own state (PCM ring and thread) lazily on the first call, so
 * the hardware layer does not need a separate init entry point. Safe to call
 * again on a reconfiguration; it only updates the handles and (re)arms the
 * playback thread.
 *
 * @param dev          Configured I2S transmit device.
 * @param slab         DMA memory slab used for both PCM and silence blocks.
 * @param block_size   Per-block size in bytes for the current configuration.
 * @param frame_dur_us Duration of one block in microseconds. Used to derive
 *                     the consumer starvation timeout, so that it scales with
 *                     the negotiated frame duration instead of being fixed.
 */
void i2s_play_setup(const struct device *dev, struct k_mem_slab *slab, uint32_t block_size,
		    uint32_t frame_dur_us);

/**
 * @brief Queue PCM data for playback (producer side).
 *
 * Copies the PCM bytes into ring blocks and returns immediately; never blocks
 * on the SAI. If the ring is full the oldest block is recycled (overrun
 * protection).
 *
 * @param data Pointer to the PCM sample buffer.
 * @param len  Number of bytes to queue.
 *
 * @return Number of bytes accepted.
 */
uint32_t i2s_play_write(const uint8_t *data, uint32_t len);

/**
 * @brief Stop playback, join the playback thread and drain the PCM ring.
 *
 * Returns once the playback thread has exited and every block it owned has
 * been returned to the slab, so the caller may safely reconfigure the stream
 * afterwards.
 */
void i2s_play_stop(void);

#endif /* BAP_BROADCAST_SINK_I2S_PLAY_H_ */
```

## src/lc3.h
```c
/**
 * @file
 * @brief Bluetooth BAP Broadcast Sink LC3 header
 *
 * This files handles all the LC3 related functionality for the sample
 *
 * Copyright (c) 2025 Nordic Semiconductor ASA
 *
 * SPDX-License-Identifier: Apache-2.0
 */
#ifndef SAMPLE_BAP_BROADCAST_SINK_LC3_H
#define SAMPLE_BAP_BROADCAST_SINK_LC3_H

#include <stdbool.h>
#include <stddef.h>

#include <zephyr/autoconf.h>
#include <zephyr/bluetooth/audio/audio.h>
#include <zephyr/bluetooth/iso.h>
#include <zephyr/device.h>
#include <zephyr/devicetree.h>
#include <zephyr/kernel.h>
#include <zephyr/logging/log.h>
#include <zephyr/net_buf.h>
#include <zephyr/shell/shell.h>
#include <zephyr/sys/clock.h>
#include <zephyr/sys/ring_buffer.h>
#include <zephyr/sys/util.h>
#include <zephyr/sys/util_macro.h>
#include <zephyr/sys/clock.h>
#include <zephyr/toolchain.h>
#include <zephyr/usb/usb_device.h>
#include <zephyr/usb/class/usb_audio.h>

#include "stream_rx.h"

#define LC3_MAX_SAMPLE_RATE_HZ     48000U
#define LC3_MAX_FRAME_DURATION_US  10000U
#define LC3_MAX_NUM_SAMPLES_MONO                                                                   \
	((LC3_MAX_FRAME_DURATION_US * LC3_MAX_SAMPLE_RATE_HZ) / USEC_PER_SEC)
#define LC3_MAX_NUM_SAMPLES_STEREO (LC3_MAX_NUM_SAMPLES_MONO * 2U)

/**
 * @brief Enables LC3 for a stream
 *
 * This will initialize the LC3 decoder given the @p stream codec configuration
 *
 * @param stream The stream to enable LC3 for

 * @retval 0 Success
 * @retval -EINVAL The stream is not LC3 codec configured or the codec configuration is invalid
 */
int lc3_enable(struct stream_rx *stream);

/**
 * @brief Disabled LC3 for a stream
 *
 * @param stream The stream to disable LC3 for

 * @retval 0 Success
 * @retval -EALREADY LC3 is not enabled for the stream
 */
int lc3_disable(struct stream_rx *stream);

/**
 * @brief Enqueue an SDU for decoding
 *
 * @param stream The stream that received the SDU
 * @param info Information about the SDU
 * @param buf The buffer of the SDU
 */
void lc3_enqueue_for_decoding(struct stream_rx *stream, const struct bt_iso_recv_info *info,
			      struct net_buf *buf);

/**
 * @brief Initialize the LC3 module
 *
 * This will start the thread if not already initialized
 *
 * @retval 0 Success
 * @retval -EALREADY Already initialized
 */
int lc3_init(void);
#endif /* SAMPLE_BAP_BROADCAST_SINK_LC3_H */
```
